# R7FA6M1AD register map
Vendor: Renesas; Series: RA6; File version: 1.2
CPU: CM4 r0p1, little endian, MPU, FPU, VTOR, 4 interrupt priority bits
Registers are 8-bit, read-write, reset 0x0 unless marked. A register's access mark holds for its fields unless they carry their own. Offsets are from the block's base; [hi:lo] are bit positions; {n}, {i} and the like mark numbered series.

## GPT328 — General PWM Timer 8
Base 0x40078800
Same registers: GPT329 0x40078900, GPT3210 0x40078A00, GPT3211 0x40078B00, GPT3212 0x40078C00
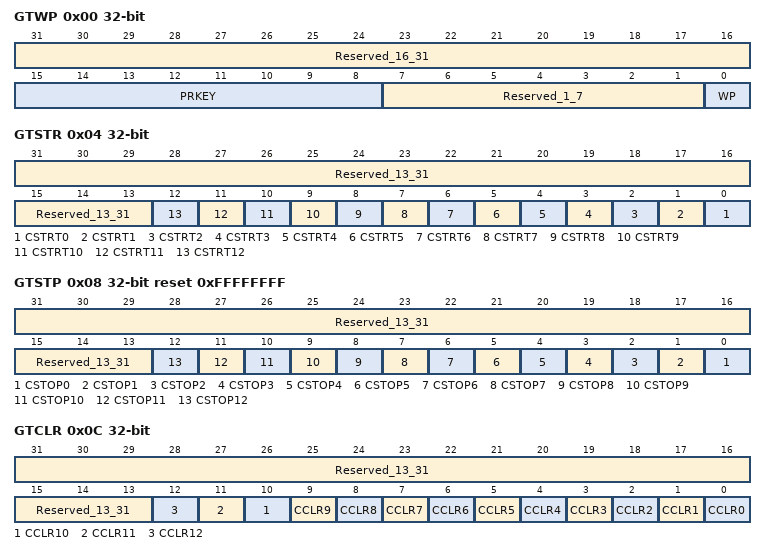
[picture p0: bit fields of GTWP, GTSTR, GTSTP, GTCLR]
0x00 GTWP 32-bit — General PWM Timer Write,Protection Register
  [31:16] Reserved_16_31 — These bits are read as 0000000000000000. The write value should be 0000000000000000.
  [15:8] PRKEY wo — GTWP Key Code
  [7:1] Reserved_1_7 — These bits are read as 0000000. The write value should be 0000000.
  [0] WP — Register Write Disable
0x04 GTSTR 32-bit — General PWM Timer Software Start Register
  [31:13] Reserved_13_31 — These bits are read as 0000000000000000000. The write value should be 0000000000000000000.
  [n] CSTRT{n} (n=0..12) — Channel {n} GTCNT Count Start Read data shows each channel's counter status (GTCR.CST bit). 0 means counter stop. 1 means counter running.
0x08 GTSTP 32-bit reset 0xFFFFFFFF — General PWM Timer Software Stop Register
  [31:13] Reserved_13_31 — These bits are read as 1111111111111111111. The write value should be 1111111111111111111.
  [n] CSTOP{n} (n=0..12) — Channel {n} GTCNT Count Stop Read data shows each channel's counter status (GTCR.CST bit). 0 means counter runnning. 1 means counter stop.
0x0C GTCLR 32-bit wo — General PWM Timer Software Clear Register
  [31:13] Reserved_13_31 — The write value should be 1111111111111111111.
  [n] CCLR{n} (n=0..12) — Channel {n} GTCNT Count Clear
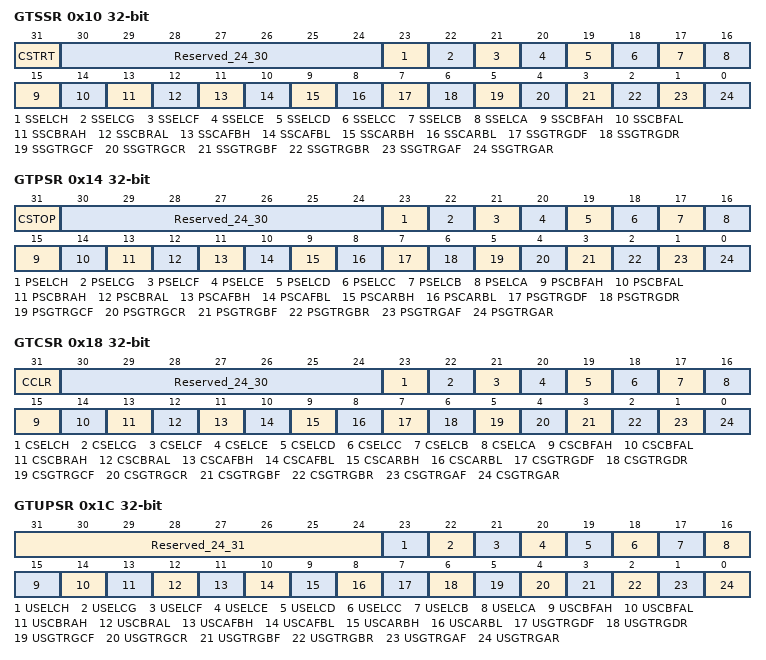
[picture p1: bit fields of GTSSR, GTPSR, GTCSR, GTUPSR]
0x10 GTSSR 32-bit — General PWM Timer Start Source Select Register
  [31] CSTRT — Software Source Counter Start Enable
  [30:24] Reserved_24_30 — These bits are read as 0000000. The write value should be 0000000.
  [23] SSELCH — ELC_GPTH Event Source Counter Start Enable
  [22] SSELCG — ELC_GPTG Event Source Counter Start Enable
  [21] SSELCF — ELC_GPTF Event Source Counter Start Enable
  [20] SSELCE — ELC_GPTE Event Source Counter Start Enable
  [19] SSELCD — ELC_GPTD Event Source Counter Start Enable
  [18] SSELCC — ELC_GPTC Event Source Counter Start Enable
  [17] SSELCB — ELC_GPTB Event Source Counter Start Enable
  [16] SSELCA — ELC_GPTA Event Source Counter Start Enable
  [15] SSCBFAH — GTIOCB Pin Falling Input during GTIOCA Value High Source Counter Start Enable
  [14] SSCBFAL — GTIOCB Pin Falling Input during GTIOCA Value Low Source Counter Start Enable
  [13] SSCBRAH — GTIOCB Pin Rising Input during GTIOCA Value High Source Counter Start Enable
  [12] SSCBRAL — GTIOCB Pin Rising Input during GTIOCA Value Low Source Counter Start Enable
  [11] SSCAFBH — GTIOCA Pin Falling Input during GTIOCB Value High Source Counter Start Enable
  [10] SSCAFBL — GTIOCA Pin Falling Input during GTIOCB Value Low Source Counter Start Enable
  [9] SSCARBH — GTIOCA Pin Rising Input during GTIOCB Value High Source Counter Start Enable
  [8] SSCARBL — GTIOCA Pin Rising Input during GTIOCB Value Low Source Counter Start Enable
  [7] SSGTRGDF — GTETRGD Pin Falling Input Source Counter Start Enable
  [6] SSGTRGDR — GTETRGD Pin Rising Input Source Counter Start Enable
  [5] SSGTRGCF — GTETRGC Pin Falling Input Source Counter Start Enable
  [4] SSGTRGCR — GTETRGC Pin Rising Input Source Counter Start Enable
  [3] SSGTRGBF — GTETRGB Pin Falling Input Source Counter Start Enable
  [2] SSGTRGBR — GTETRGB Pin Rising Input Source Counter Start Enable
  [1] SSGTRGAF — GTETRGA Pin Falling Input Source Counter Start Enable
  [0] SSGTRGAR — GTETRGA Pin Rising Input Source Counter Start Enable
0x14 GTPSR 32-bit — General PWM Timer Stop Source Select Register
  [31] CSTOP — Software Source Counter Stop Enable
  [30:24] Reserved_24_30 — These bits are read as 0000000. The write value should be 0000000.
  [23] PSELCH — ELC_GPTH Event Source Counter Stop Enable
  [22] PSELCG — ELC_GPTG Event Source Counter Stop Enable
  [21] PSELCF — ELC_GPTF Event Source Counter Stop Enable
  [20] PSELCE — ELC_GPTE Event Source Counter Stop Enable
  [19] PSELCD — ELC_GPTD Event Source Counter Stop Enable
  [18] PSELCC — ELC_GPTC Event Source Counter Stop Enable
  [17] PSELCB — ELC_GPTB Event Source Counter Stop Enable
  [16] PSELCA — ELC_GPTA Event Source Counter Stop Enable
  [15] PSCBFAH — GTIOCB Pin Falling Input during GTIOCA Value High Source Counter Stop Enable
  [14] PSCBFAL — GTIOCB Pin Falling Input during GTIOCA Value Low Source Counter Stop Enable
  [13] PSCBRAH — GTIOCB Pin Rising Input during GTIOCA Value High Source Counter Stop Enable
  [12] PSCBRAL — GTIOCB Pin Rising Input during GTIOCA Value Low Source Counter Stop Enable
  [11] PSCAFBH — GTIOCA Pin Falling Input during GTIOCB Value High Source Counter Stop Enable
  [10] PSCAFBL — GTIOCA Pin Falling Input during GTIOCB Value Low Source Counter Stop Enable
  [9] PSCARBH — GTIOCA Pin Rising Input during GTIOCB Value High Source Counter Stop Enable
  [8] PSCARBL — GTIOCA Pin Rising Input during GTIOCB Value Low Source Counter Stop Enable
  [7] PSGTRGDF — GTETRGD Pin Falling Input Source Counter Stop Enable
  [6] PSGTRGDR — GTETRGD Pin Rising Input Source Counter Stop Enable
  [5] PSGTRGCF — GTETRGC Pin Falling Input Source Counter Stop Enable
  [4] PSGTRGCR — GTETRGC Pin Rising Input Source Counter Stop Enable
  [3] PSGTRGBF — GTETRGB Pin Falling Input Source Counter Stop Enable
  [2] PSGTRGBR — GTETRGB Pin Rising Input Source Counter Stop Enable
  [1] PSGTRGAF — GTETRGA Pin Falling Input Source Counter Stop Enable
  [0] PSGTRGAR — GTETRGA Pin Rising Input Source Counter Stop Enable
0x18 GTCSR 32-bit — General PWM Timer Clear Source Select Register
  [31] CCLR — Software Source Counter Clear Enable
  [30:24] Reserved_24_30 — These bits are read as 0000000. The write value should be 0000000.
  [23] CSELCH — ELC_GPTH Event Source Counter Clear Enable
  [22] CSELCG — ELC_GPTG Event Source Counter Clear Enable
  [21] CSELCF — ELC_GPTF Event Source Counter Clear Enable
  [20] CSELCE — ELC_GPTE Event Source Counter Clear Enable
  [19] CSELCD — ELC_GPTD Event Source Counter Clear Enable
  [18] CSELCC — ELC_GPTC Event Source Counter Clear Enable
  [17] CSELCB — ELC_GPTB Event Source Counter Clear Enable
  [16] CSELCA — ELC_GPTA Event Source Counter Clear Enable
  [15] CSCBFAH — GTIOCB Pin Falling Input during GTIOCA Value High Source Counter Clear Enable
  [14] CSCBFAL — GTIOCB Pin Falling Input during GTIOCA Value Low Source Counter Clear Enable
  [13] CSCBRAH — GTIOCB Pin Rising Input during GTIOCA Value High Source Counter Clear Enable
  [12] CSCBRAL — GTIOCB Pin Rising Input during GTIOCA Value Low Source Counter Clear Enable
  [11] CSCAFBH — GTIOCA Pin Falling Input during GTIOCB Value High Source Counter Clear Enable
  [10] CSCAFBL — GTIOCA Pin Falling Input during GTIOCB Value Low Source Counter Clear Enable
  [9] CSCARBH — GTIOCA Pin Rising Input during GTIOCB Value High Source Counter Clear Enable
  [8] CSCARBL — GTIOCA Pin Rising Input during GTIOCB Value Low Source Counter Clear Enable
  [7] CSGTRGDF — GTETRGD Pin Falling Input Source Counter Clear Enable
  [6] CSGTRGDR — GTETRGD Pin Rising Input Source Counter Clear Enable
  [5] CSGTRGCF — GTETRGC Pin Falling Input Source Counter Clear Enable
  [4] CSGTRGCR — GTETRGC Pin Rising Input Source Counter Clear Enable
  [3] CSGTRGBF — GTETRGB Pin Falling Input Source Counter Clear Enable
  [2] CSGTRGBR — GTETRGB Pin Rising Input Source Counter Clear Enable
  [1] CSGTRGAF — GTETRGA Pin Falling Input Source Counter Clear Enable
  [0] CSGTRGAR — GTETRGA Pin Rising Input Source Counter Clear Enable
0x1C GTUPSR 32-bit — General PWM Timer Up Count Source Select Register
  [31:24] Reserved_24_31 — These bits are read as 00000000. The write value should be 00000000.
  [23] USELCH — ELC_GPTH Event Source Counter Count Up Enable
  [22] USELCG — ELC_GPTG Event Source Counter Count Up Enable
  [21] USELCF — ELC_GPTF Event Source Counter Count Up Enable
  [20] USELCE — ELC_GPTE Event Source Counter Count Up Enable
  [19] USELCD — ELC_GPTD Event Source Counter Count Up Enable
  [18] USELCC — ELC_GPTC Event Source Counter Count Up Enable
  [17] USELCB — ELC_GPTB Event Source Counter Count Up Enable
  [16] USELCA — ELC_GPTA Event Source Counter Count Up Enable
  [15] USCBFAH — GTIOCB Pin Falling Input during GTIOCA Value High Source Counter Count Up Enable
  [14] USCBFAL — GTIOCB Pin Falling Input during GTIOCA Value Low Source Counter Count Up Enable
  [13] USCBRAH — GTIOCB Pin Rising Input during GTIOCA Value High Source Counter Count Up Enable
  [12] USCBRAL — GTIOCB Pin Rising Input during GTIOCA Value Low Source Counter Count Up Enable
  [11] USCAFBH — GTIOCA Pin Falling Input during GTIOCB Value High Source Counter Count Up Enable
  [10] USCAFBL — GTIOCA Pin Falling Input during GTIOCB Value Low Source Counter Count Up Enable
  [9] USCARBH — GTIOCA Pin Rising Input during GTIOCB Value High Source Counter Count Up Enable
  [8] USCARBL — GTIOCA Pin Rising Input during GTIOCB Value Low Source Counter Count Up Enable
  [7] USGTRGDF — GTETRGD Pin Falling Input Source Counter Count Up Enable
  [6] USGTRGDR — GTETRGD Pin Rising Input Source Counter Count Up Enable
  [5] USGTRGCF — GTETRGC Pin Falling Input Source Counter Count Up Enable
  [4] USGTRGCR — GTETRGC Pin Rising Input Source Counter Count Up Enable
  [3] USGTRGBF — GTETRGB Pin Falling Input Source Counter Count Up Enable
  [2] USGTRGBR — GTETRGB Pin Rising Input Source Counter Count Up Enable
  [1] USGTRGAF — GTETRGA Pin Falling Input Source Counter Count Up Enable
  [0] USGTRGAR — GTETRGA Pin Rising Input Source Counter Count Up Enable
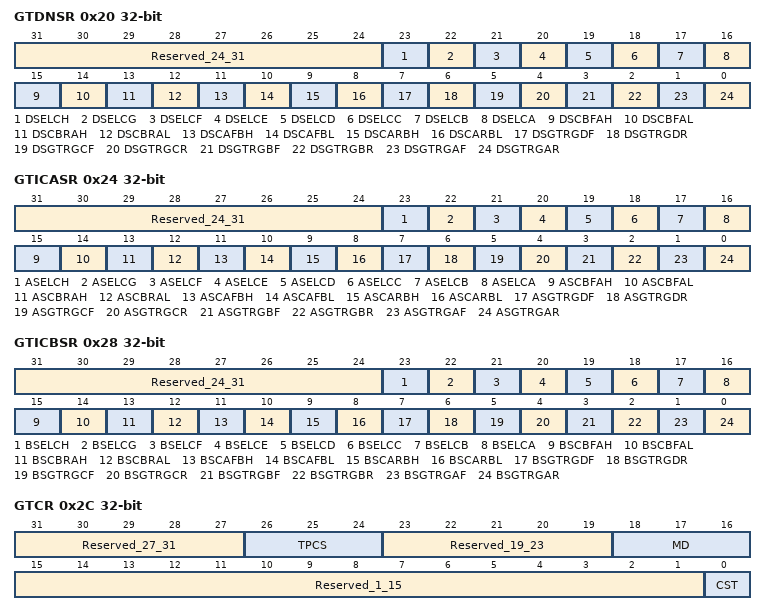
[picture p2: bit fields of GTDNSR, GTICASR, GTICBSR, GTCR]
0x20 GTDNSR 32-bit — General PWM Timer Down Count Source Select Register
  [31:24] Reserved_24_31 — These bits are read as 00000000. The write value should be 00000000.
  [23] DSELCH — ELC_GPTH Event Source Counter Count Down Enable
  [22] DSELCG — ELC_GPTG Event Source Counter Count Down Enable
  [21] DSELCF — ELC_GPTF Event Source Counter Count Down Enable
  [20] DSELCE — ELC_GPTE Event Source Counter Count Down Enable
  [19] DSELCD — ELC_GPTD Event Source Counter Count Down Enable
  [18] DSELCC — ELC_GPTC Event Source Counter Count Down Enable
  [17] DSELCB — ELC_GPTB Event Source Counter Count Down Enable
  [16] DSELCA — ELC_GPTA Event Source Counter Count Down Enable
  [15] DSCBFAH — GTIOCB Pin Falling Input during GTIOCA Value High Source Counter Count Down Enable
  [14] DSCBFAL — GTIOCB Pin Falling Input during GTIOCA Value Low Source Counter Count Down Enable
  [13] DSCBRAH — GTIOCB Pin Rising Input during GTIOCA Value High Source Counter Count Down Enable
  [12] DSCBRAL — GTIOCB Pin Rising Input during GTIOCA Value Low Source Counter Count Down Enable
  [11] DSCAFBH — GTIOCA Pin Falling Input during GTIOCB Value High Source Counter Count Down Enable
  [10] DSCAFBL — GTIOCA Pin Falling Input during GTIOCB Value Low Source Counter Count Down Enable
  [9] DSCARBH — GTIOCA Pin Rising Input during GTIOCB Value High Source Counter Count Down Enable
  [8] DSCARBL — GTIOCA Pin Rising Input during GTIOCB Value Low Source Counter Count Down Enable
  [7] DSGTRGDF — GTETRGD Pin Falling Input Source Counter Count Down Enable
  [6] DSGTRGDR — GTETRGD Pin Rising Input Source Counter Count Down Enable
  [5] DSGTRGCF — GTETRGC Pin Falling Input Source Counter Count Down Enable
  [4] DSGTRGCR — GTETRGC Pin Rising Input Source Counter Count Down Enable
  [3] DSGTRGBF — GTETRGB Pin Falling Input Source Counter Count Down Enable
  [2] DSGTRGBR — GTETRGB Pin Rising Input Source Counter Count Down Enable
  [1] DSGTRGAF — GTETRGA Pin Falling Input Source Counter Count Down Enable
  [0] DSGTRGAR — GTETRGA Pin Rising Input Source Counter Count Down Enable
0x24 GTICASR 32-bit — General PWM Timer Input Capture Source Select Register A
  [31:24] Reserved_24_31 — These bits are read as 00000000. The write value should be 00000000.
  [23] ASELCH — ELC_GPTH Event Source GTCCRA Input Capture Enable
  [22] ASELCG — ELC_GPTG Event Source GTCCRA Input Capture Enable
  [21] ASELCF — ELC_GPTF Event Source GTCCRA Input Capture Enable
  [20] ASELCE — ELC_GPTE Event Source GTCCRA Input Capture Enable
  [19] ASELCD — ELC_GPTD Event Source GTCCRA Input Capture Enable
  [18] ASELCC — ELC_GPTC Event Source GTCCRA Input Capture Enable
  [17] ASELCB — ELC_GPTB Event Source GTCCRA Input Capture Enable
  [16] ASELCA — ELC_GPTA Event Source GTCCRA Input Capture Enable
  [15] ASCBFAH — GTIOCB Pin Falling Input during GTIOCA Value High Source GTCCRA Input Capture Enable
  [14] ASCBFAL — GTIOCB Pin Falling Input during GTIOCA Value Low Source GTCCRA Input Capture Enable
  [13] ASCBRAH — GTIOCB Pin Rising Input during GTIOCA Value High Source GTCCRA Input Capture Enable
  [12] ASCBRAL — GTIOCB Pin Rising Input during GTIOCA Value Low Source GTCCRA Input Capture Enable
  [11] ASCAFBH — GTIOCA Pin Falling Input during GTIOCB Value High Source GTCCRA Input Capture Enable
  [10] ASCAFBL — GTIOCA Pin Falling Input during GTIOCB Value Low Source GTCCRA Input Capture Enable
  [9] ASCARBH — GTIOCA Pin Rising Input during GTIOCB Value High Source GTCCRA Input Capture Enable
  [8] ASCARBL — GTIOCA Pin Rising Input during GTIOCB Value Low Source GTCCRA Input Capture Enable
  [7] ASGTRGDF — GTETRGD Pin Falling Input Source GTCCRA Input Capture Enable
  [6] ASGTRGDR — GTETRGD Pin Rising Input Source GTCCRA Input Capture Enable
  [5] ASGTRGCF — GTETRGC Pin Falling Input Source GTCCRA Input Capture Enable
  [4] ASGTRGCR — GTETRGC Pin Rising Input Source GTCCRA Input Capture Enable
  [3] ASGTRGBF — GTETRGB Pin Falling Input Source GTCCRA Input Capture Enable
  [2] ASGTRGBR — GTETRGB Pin Rising Input Source GTCCRA Input Capture Enable
  [1] ASGTRGAF — GTETRGA Pin Falling Input Source GTCCRA Input Capture Enable
  [0] ASGTRGAR — GTETRGA Pin Rising Input Source GTCCRA Input Capture Enable
0x28 GTICBSR 32-bit — General PWM Timer Input Capture Source Select Register B
  [31:24] Reserved_24_31 — These bits are read as 00000000. The write value should be 00000000.
  [23] BSELCH — ELC_GPTH Event Source GTCCRB Input Capture Enable
  [22] BSELCG — ELC_GPTG Event Source GTCCRB Input Capture Enable
  [21] BSELCF — ELC_GPTF Event Source GTCCRB Input Capture Enable
  [20] BSELCE — ELC_GPTE Event Source GTCCRB Input Capture Enable
  [19] BSELCD — ELC_GPTD Event Source GTCCRB Input Capture Enable
  [18] BSELCC — ELC_GPTC Event Source GTCCRB Input Capture Enable
  [17] BSELCB — ELC_GPTB Event Source GTCCRB Input Capture Enable
  [16] BSELCA — ELC_GPTA Event Source GTCCRB Input Capture Enable
  [15] BSCBFAH — GTIOCB Pin Falling Input during GTIOCA Value High Source GTCCRB Input Capture Enable
  [14] BSCBFAL — GTIOCB Pin Falling Input during GTIOCA Value Low Source GTCCRB Input Capture Enable
  [13] BSCBRAH — GTIOCB Pin Rising Input during GTIOCA Value High Source GTCCRB Input Capture Enable
  [12] BSCBRAL — GTIOCB Pin Rising Input during GTIOCA Value Low Source GTCCRB Input Capture Enable
  [11] BSCAFBH — GTIOCA Pin Falling Input during GTIOCB Value High Source GTCCRB Input Capture Enable
  [10] BSCAFBL — GTIOCA Pin Falling Input during GTIOCB Value Low Source GTCCRB Input Capture Enable
  [9] BSCARBH — GTIOCA Pin Rising Input during GTIOCB Value High Source GTCCRB Input Capture Enable
  [8] BSCARBL — GTIOCA Pin Rising Input during GTIOCB Value Low Source GTCCRB Input Capture Enable
  [7] BSGTRGDF — GTETRGD Pin Falling Input Source GTCCRB Input Capture Enable
  [6] BSGTRGDR — GTETRGD Pin Rising Input Source GTCCRB Input Capture Enable
  [5] BSGTRGCF — GTETRGC Pin Falling Input Source GTCCRB Input Capture Enable
  [4] BSGTRGCR — GTETRGC Pin Rising Input Source GTCCRB Input Capture Enable
  [3] BSGTRGBF — GTETRGB Pin Falling Input Source GTCCRB Input Capture Enable
  [2] BSGTRGBR — GTETRGB Pin Rising Input Source GTCCRB Input Capture Enable
  [1] BSGTRGAF — GTETRGA Pin Falling Input Source GTCCRB Input Capture Enable
  [0] BSGTRGAR — GTETRGA Pin Rising Input Source GTCCRB Input Capture Enable
0x2C GTCR 32-bit — General PWM Timer Control Register
  [31:27] Reserved_27_31 — These bits are read as 00000. The write value should be 00000.
  [26:24] TPCS — Timer Prescaler Select
  [23:19] Reserved_19_23 — These bits are read as 00000. The write value should be 00000.
  [18:16] MD — Mode Select
  [15:1] Reserved_1_15 — These bits are read as 000000000000000. The write value should be 000000000000000.
  [0] CST — Count Start
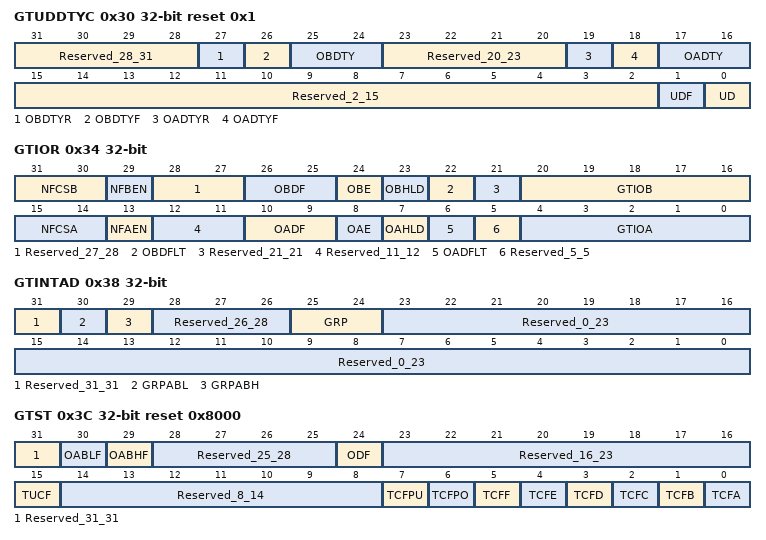
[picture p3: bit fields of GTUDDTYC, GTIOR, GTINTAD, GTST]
0x30 GTUDDTYC 32-bit reset 0x1 — General PWM Timer Count Direction and Duty Setting Register
  [31:28] Reserved_28_31 — These bits are read as 0000. The write value should be 0000.
  [27] OBDTYR — GTIOCB Output Value Selecting after Releasing 0 percent/100 percent Duty Setting
  [26] OBDTYF — Forcible GTIOCB Output Duty Setting
  [25:24] OBDTY — GTIOCB Output Duty Setting
  [23:20] Reserved_20_23 — These bits are read as 0000. The write value should be 0000.
  [19] OADTYR — GTIOCA Output Value Selecting after Releasing 0 percent/100 percent Duty Setting
  [18] OADTYF — Forcible GTIOCA Output Duty Setting
  [17:16] OADTY — GTIOCA Output Duty Setting
  [15:2] Reserved_2_15 — These bits are read as 00000000000000. The write value should be 00000000000000.
  [1] UDF — Forcible Count Direction Setting
  [0] UD — Count Direction Setting
0x34 GTIOR 32-bit — General PWM Timer I/O Control Register
  [31:30] NFCSB — Noise Filter B Sampling Clock Select
  [29] NFBEN — Noise Filter B Enable
  [28:27] Reserved_27_28 — These bits are read as 00. The write value should be 00.
  [26:25] OBDF — GTIOCB Pin Disable Value Setting
  [24] OBE — GTIOCB Pin Output Enable
  [23] OBHLD — GTIOCB Pin Output Setting at the Start/Stop Count
  [22] OBDFLT — GTIOCB Pin Output Value Setting at the Count Stop
  [21] Reserved_21_21 — This bit is read as 0. The write value should be 0.
  [20:16] GTIOB — GTIOCB Pin Function Select
  [15:14] NFCSA — Noise Filter A Sampling Clock Select
  [13] NFAEN — Noise Filter A Enable
  [12:11] Reserved_11_12 — These bits are read as 00. The write value should be 00.
  [10:9] OADF — GTIOCA Pin Disable Value Setting
  [8] OAE — GTIOCA Pin Output Enable
  [7] OAHLD — GTIOCA Pin Output Setting at the Start/Stop Count
  [6] OADFLT — GTIOCA Pin Output Value Setting at the Count Stop
  [5] Reserved_5_5 — This bit is read as 0. The write value should be 0.
  [4:0] GTIOA — GTIOCA Pin Function Select
0x38 GTINTAD 32-bit — General PWM Timer Interrupt Output Setting Register
  [31] Reserved_31_31 — This bit is read as 0. The write value should be 0.
  [30] GRPABL — Same Time Output Level Low Disable Request Enable
  [29] GRPABH — Same Time Output Level High Disable Request Enable
  [28:26] Reserved_26_28 — These bits are read as 000. The write value should be 000.
  [25:24] GRP — Output Disable Source Select
  [23:0] Reserved_0_23 — These bits are read as 000000000000000000000000. The write value should be 000000000000000000000000.
0x3C GTST 32-bit reset 0x8000 — General PWM Timer Status Register
  [31] Reserved_31_31 — This bit is read as 0. The write value should be 0.
  [30] OABLF ro — Same Time Output Level Low Disable Request Enable
  [29] OABHF ro — Same Time Output Level High Disable Request Enable
  [28:25] Reserved_25_28 — These bits are read as 0000. The write value should be 0000.
  [24] ODF ro — Output Disable Flag
  [23:16] Reserved_16_23 — These bits are read as 00000000. The write value should be 00000000.
  [15] TUCF ro — Count Direction Flag
  [14:8] Reserved_8_14 — These bits are read as 0000000. The write value should be 0000000.
  [7] TCFPU — Underflow Flag
  [6] TCFPO — Overflow Flag
  [5] TCFF — Input Compare Match Flag F
  [4] TCFE — Input Compare Match Flag E
  [3] TCFD — Input Compare Match Flag D
  [2] TCFC — Input Compare Match Flag C
  [1] TCFB — Input Capture/Compare Match Flag B
  [0] TCFA — Input Capture/Compare Match Flag A
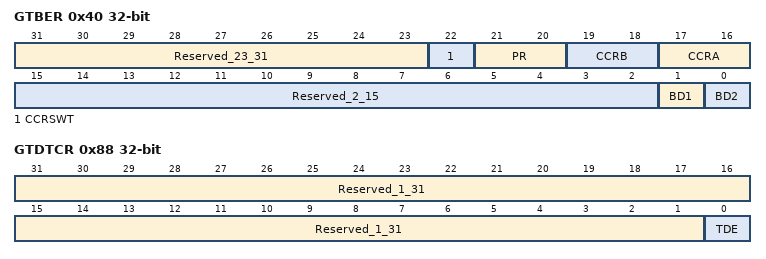
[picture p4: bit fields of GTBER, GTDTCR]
0x40 GTBER 32-bit — General PWM Timer Buffer Enable Register
  [31:23] Reserved_23_31 — These bits are read as 000000000. The write value should be 000000000.
  [22] CCRSWT wo — GTCCRA and GTCCRB Forcible Buffer Operation This bit is read as 0.
  [21:20] PR — GTPR Buffer Operation
  [19:18] CCRB — GTCCRB Buffer Operation
  [17:16] CCRA — GTCCRA Buffer Operation
  [15:2] Reserved_2_15 — These bits are read as 00000000000000. The write value should be 00000000000000.
  [1] BD1 — GTPR Buffer Operation Disable
  [0] BD2 — GTCCR Buffer Operation Disable
0x48 GTCNT 32-bit — General PWM Timer Counter
  [31:0] GTCNT — Counter
0x4C GTCCRA 32-bit reset 0xFFFFFFFF — General PWM Timer Compare Capture Register A
  [31:0] GTCCRA — Compare Capture Register A
0x50 GTCCRB 32-bit reset 0xFFFFFFFF — General PWM Timer Compare Capture Register B
  [31:0] GTCCRB — Compare Capture Register B
0x54 GTCCRC 32-bit reset 0xFFFFFFFF — General PWM Timer Compare Capture Register C
  [31:0] GTCCRC — Compare Capture Register C
0x58 GTCCRE 32-bit reset 0xFFFFFFFF — General PWM Timer Compare Capture Register E
  [31:0] GTCCRE — Compare Capture Register E
0x5C GTCCRD 32-bit reset 0xFFFFFFFF — General PWM Timer Compare Capture Register D
  [31:0] GTCCRD — Compare Capture Register D
0x60 GTCCRF 32-bit reset 0xFFFFFFFF — General PWM Timer Compare Capture Register F
  [31:0] GTCCRF — Compare Capture Register F
0x64 GTPR 32-bit reset 0xFFFFFFFF — General PWM Timer Cycle Setting Register
  [31:0] GTPR — Cycle Setting Register
0x68 GTPBR 32-bit reset 0xFFFFFFFF — General PWM Timer Cycle Setting Buffer Register
  [31:0] GTPBR — Cycle Setting Buffer Register
0x88 GTDTCR 32-bit — General PWM Timer Dead Time Control Register
  [31:1] Reserved_1_31 — These bits are read as 0000000000000000000000000000000. The write value should be 0000000000000000000000000000000.
  [0] TDE — Negative,Phase Waveform Setting
0x8C GTDVU 32-bit reset 0xFFFFFFFF — General PWM Timer Dead Time Value Register U
  [31:0] GTDVU — Dead Time Value Register U
